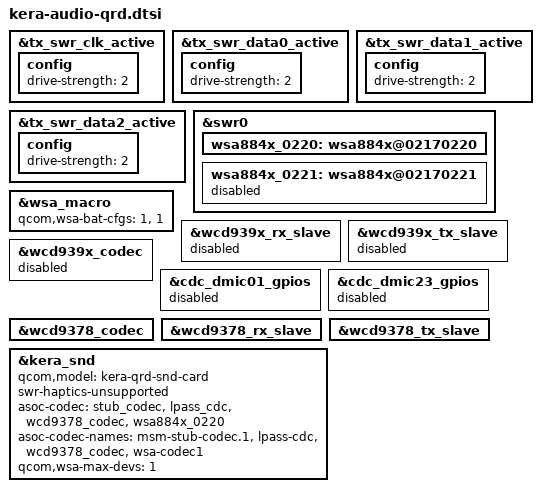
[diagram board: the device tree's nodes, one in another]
// SPDX-License-Identifier: BSD-3-Clause
/*
 * Copyright (c) 2023-2024 Qualcomm Innovation Center, Inc. All rights reserved.
 */
#include "kera-audio-overlay.dtsi"
#include "kera-audio-lpass-reg.dtsi"

&tx_swr_clk_active {
	config {
		drive-strength = <2>;
	};
};

&tx_swr_data0_active {
	config {
		drive-strength = <2>;
	};
};

&tx_swr_data1_active {
	config {
		drive-strength = <2>;
	};
};

&tx_swr_data2_active {
	config {
		drive-strength = <2>;
	};
};

&swr0 {
	wsa884x_0220: wsa884x@02170220 {
		status = "okay";
	};

	wsa884x_0221: wsa884x@02170221 {
		status = "disabled";
	};
};

&wsa_macro {
	qcom,wsa-bat-cfgs = <1>, <1>;
};

&wcd939x_rx_slave {
	status = "disabled";
};

&wcd939x_tx_slave {
	status = "disabled";
};

&wcd939x_codec {
	status = "disabled";
};

&cdc_dmic01_gpios {
	status = "disabled";
};

&cdc_dmic23_gpios {
	status = "disabled";
};

&wcd9378_codec {
	status = "okay";
};

&wcd9378_rx_slave {
	status = "okay";
};

&wcd9378_tx_slave {
	status = "okay";
};

&kera_snd {
	qcom,model = "kera-qrd-snd-card";
	swr-haptics-unsupported;
	asoc-codec  = <&stub_codec>, <&lpass_cdc>,
			<&wcd9378_codec>, <&wsa884x_0220>;
	asoc-codec-names = "msm-stub-codec.1", "lpass-cdc",
			"wcd9378_codec", "wsa-codec1";
	qcom,wsa-max-devs = <1>;
};
